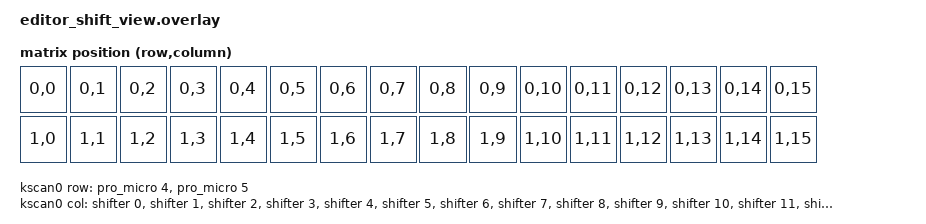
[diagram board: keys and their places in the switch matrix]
/* Generated by ZMK Editor from editor_shift_view.editor.json. */

#include <dt-bindings/zmk/matrix_transform.h>
#include <physical_layouts.dtsi>

/ {
    chosen {
        zmk,kscan = &kscan0;
        zmk,physical-layout = &editor_shift_view_layout;
    };

    kscan0: kscan {
        compatible = "zmk,kscan-gpio-matrix";
        wakeup-source;
        diode-direction = "col2row";

        row-gpios
            = <&pro_micro  4 (GPIO_ACTIVE_HIGH | GPIO_PULL_DOWN)>
            , <&pro_micro  5 (GPIO_ACTIVE_HIGH | GPIO_PULL_DOWN)>
            ;

        col-gpios
            = <&shifter  0 GPIO_ACTIVE_HIGH>
            , <&shifter  1 GPIO_ACTIVE_HIGH>
            , <&shifter  2 GPIO_ACTIVE_HIGH>
            , <&shifter  3 GPIO_ACTIVE_HIGH>
            , <&shifter  4 GPIO_ACTIVE_HIGH>
            , <&shifter  5 GPIO_ACTIVE_HIGH>
            , <&shifter  6 GPIO_ACTIVE_HIGH>
            , <&shifter  7 GPIO_ACTIVE_HIGH>
            , <&shifter  8 GPIO_ACTIVE_HIGH>
            , <&shifter  9 GPIO_ACTIVE_HIGH>
            , <&shifter 10 GPIO_ACTIVE_HIGH>
            , <&shifter 11 GPIO_ACTIVE_HIGH>
            , <&shifter 12 GPIO_ACTIVE_HIGH>
            , <&shifter 13 GPIO_ACTIVE_HIGH>
            , <&shifter 14 GPIO_ACTIVE_HIGH>
            , <&shifter 15 GPIO_ACTIVE_HIGH>
            ;
    };

    default_transform: keymap_transform_0 {
        compatible = "zmk,matrix-transform";
        rows = <2>;
        columns = <16>;
        map = <
RC(0,0)  RC(0,1)  RC(0,2)  RC(0,3)  RC(0,4)  RC(0,5)  RC(0,6)  RC(0,7)  RC(0,8)  RC(0,9)  RC(0,10) RC(0,11) RC(0,12) RC(0,13) RC(0,14) RC(0,15)
RC(1,0)  RC(1,1)  RC(1,2)  RC(1,3)  RC(1,4)  RC(1,5)  RC(1,6)  RC(1,7)  RC(1,8)  RC(1,9)  RC(1,10) RC(1,11) RC(1,12) RC(1,13) RC(1,14) RC(1,15)
        >;
    };

    editor_shift_view_layout: editor_shift_view_layout {
        compatible = "zmk,physical-layout";
        display-name = "Shift View";
        transform = <&default_transform>;

        keys  //                     w   h    x    y     rot   rx   ry
            = <&key_physical_attrs 100 100    0    0      0    0    0>
            , <&key_physical_attrs 100 100  100    0      0    0    0>
            , <&key_physical_attrs 100 100  200    0      0    0    0>
            , <&key_physical_attrs 100 100  300    0      0    0    0>
            , <&key_physical_attrs 100 100  400    0      0    0    0>
            , <&key_physical_attrs 100 100  500    0      0    0    0>
            , <&key_physical_attrs 100 100  600    0      0    0    0>
            , <&key_physical_attrs 100 100  700    0      0    0    0>
            , <&key_physical_attrs 100 100  800    0      0    0    0>
            , <&key_physical_attrs 100 100  900    0      0    0    0>
            , <&key_physical_attrs 100 100 1000    0      0    0    0>
            , <&key_physical_attrs 100 100 1100    0      0    0    0>
            , <&key_physical_attrs 100 100 1200    0      0    0    0>
            , <&key_physical_attrs 100 100 1300    0      0    0    0>
            , <&key_physical_attrs 100 100 1400    0      0    0    0>
            , <&key_physical_attrs 100 100 1500    0      0    0    0>
            , <&key_physical_attrs 100 100    0  100      0    0    0>
            , <&key_physical_attrs 100 100  100  100      0    0    0>
            , <&key_physical_attrs 100 100  200  100      0    0    0>
            , <&key_physical_attrs 100 100  300  100      0    0    0>
            , <&key_physical_attrs 100 100  400  100      0    0    0>
            , <&key_physical_attrs 100 100  500  100      0    0    0>
            , <&key_physical_attrs 100 100  600  100      0    0    0>
            , <&key_physical_attrs 100 100  700  100      0    0    0>
            , <&key_physical_attrs 100 100  800  100      0    0    0>
            , <&key_physical_attrs 100 100  900  100      0    0    0>
            , <&key_physical_attrs 100 100 1000  100      0    0    0>
            , <&key_physical_attrs 100 100 1100  100      0    0    0>
            , <&key_physical_attrs 100 100 1200  100      0    0    0>
            , <&key_physical_attrs 100 100 1300  100      0    0    0>
            , <&key_physical_attrs 100 100 1400  100      0    0    0>
            , <&key_physical_attrs 100 100 1500  100      0    0    0>
            ;
    };
};

&pinctrl {
    nice_view_spi_default: nice_view_spi_default {
        group1 {
            psels = <NRF_PSEL(SPIM_SCK, 0, 20)>,
                <NRF_PSEL(SPIM_MOSI, 0, 17)>;
        };
    };
    nice_view_spi_sleep: nice_view_spi_sleep {
        group1 {
            psels = <NRF_PSEL(SPIM_SCK, 0, 20)>,
                <NRF_PSEL(SPIM_MOSI, 0, 17)>;
            low-power-enable;
        };
    };
};

nice_view_spi: &pro_micro_spi {
    status = "okay";
    compatible = "nordic,nrf-spim";
    pinctrl-0 = <&nice_view_spi_default>;
    pinctrl-1 = <&nice_view_spi_sleep>;
    pinctrl-names = "default", "sleep";
    cs-gpios = <&pro_micro 1 GPIO_ACTIVE_HIGH>, <&pro_micro 0 GPIO_ACTIVE_LOW>;

    shifter: 595@1 {
        compatible = "zmk,gpio-595";
        status = "okay";
        gpio-controller;
        spi-max-frequency = <1000000>;
        reg = <1>;
        #gpio-cells = <2>;
        ngpios = <16>;
    };
};

&pro_micro_i2c {
    status = "disabled";
};
